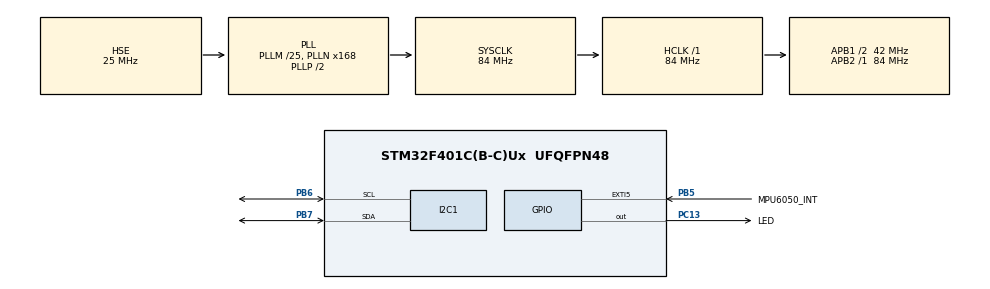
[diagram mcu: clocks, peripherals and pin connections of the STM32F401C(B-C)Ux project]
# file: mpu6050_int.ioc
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I2C1.I2C_Mode=I2C_Standard
Mcu.Family=STM32F4
Mcu.Name=STM32F401C(B-C)Ux
Mcu.Package=UFQFPN48
NVIC.EXTI9_5_IRQn=true\:2\:0\:true\:false\:true\:true\:true\:true
NVIC.I2C1_ER_IRQn=true\:2\:0\:true\:false\:true\:true\:true\:true
NVIC.I2C1_EV_IRQn=true\:2\:0\:true\:false\:true\:true\:true\:true
NVIC.PriorityGroup=NVIC_PRIORITYGROUP_4
PA13.Mode=Trace_Asynchronous_SW
PA13.Signal=SYS_JTMS-SWDIO
PA14.Mode=Trace_Asynchronous_SW
PA14.Signal=SYS_JTCK-SWCLK
PB3.Mode=Trace_Asynchronous_SW
PB3.Signal=SYS_JTDO-SWO
PB5.GPIO_Label=MPU6050_INT
PB5.GPIO_PuPd=GPIO_PULLDOWN
PB5.Signal=GPXTI5
PB6.Mode=I2C
PB6.Signal=I2C1_SCL
PB7.Mode=I2C
PB7.Signal=I2C1_SDA
PC13-ANTI_TAMP.GPIO_Label=LED
PC13-ANTI_TAMP.Signal=GPIO_Output
PH0\ -\ OSC_IN.Mode=HSE-External-Oscillator
PH0\ -\ OSC_IN.Signal=RCC_OSC_IN
PH1\ -\ OSC_OUT.Mode=HSE-External-Oscillator
PH1\ -\ OSC_OUT.Signal=RCC_OSC_OUT
ProjectManager.HeapSize=0x200
ProjectManager.StackSize=0x400
ProjectManager.TargetToolchain=STM32CubeIDE
RCC.48MHZClocksFreq_Value=42000000
RCC.AHBFreq_Value=84000000
RCC.APB1CLKDivider=RCC_HCLK_DIV2
RCC.APB1Freq_Value=42000000
RCC.APB1TimFreq_Value=84000000
RCC.APB2Freq_Value=84000000
RCC.APB2TimFreq_Value=84000000
RCC.CortexFreq_Value=84000000
RCC.HCLKFreq_Value=84000000
RCC.HSE_VALUE=25000000
RCC.HSI_VALUE=16000000
RCC.LSE_VALUE=32768
RCC.PLLM=25
RCC.PLLN=168
RCC.PLLSourceVirtual=RCC_PLLSOURCE_HSE
RCC.SYSCLKFreq_VALUE=84000000
RCC.SYSCLKSource=RCC_SYSCLKSOURCE_PLLCLK
RCC.VCOOutputFreq_Value=168000000
board=custom

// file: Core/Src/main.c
/* USER CODE BEGIN Header */
/**
  ******************************************************************************
  * @file           : main.c
  * @brief          : Main program body
  ******************************************************************************
  * @attention
  *
  * Copyright (c) 2023 STMicroelectronics.
  * All rights reserved.
  *
  * This software is licensed under terms that can be found in the LICENSE file
  * in the root directory of this software component.
  * If no LICENSE file comes with this software, it is provided AS-IS.
  *
  ******************************************************************************
  */
/* USER CODE END Header */
#include "main.h"
#include "i2c.h"
#include "gpio.h"

/* USER CODE BEGIN Includes */
#include "mpu6050.h"
#include "stdio.h"
/* USER CODE END Includes */

void SystemClock_Config(void);
/* USER CODE BEGIN PFP */
int _write(int file, char *ptr, int len){
	int i = 0;
	for (i = 0; i < len; i++)
		ITM_SendChar((*ptr++));
	return len;
}

/* USER CODE END PFP */

int main(void)
{

  /* MCU Configuration--------------------------------------------------------*/

  /* Reset of all peripherals, Initializes the Flash interface and the Systick. */
  HAL_Init();

  /* Configure the system clock */
  SystemClock_Config();

  /* Initialize all configured peripherals */
  MX_GPIO_Init();
  MX_I2C1_Init();
  /* USER CODE BEGIN 2 */
  uint8_t res = mpu6050_init(&hi2c1);
  printf("res : %d",res);
	  uint8_t check=0;
  /* USER CODE END 2 */

  /* Infinite loop */
  while (1)
  {
	  HAL_StatusTypeDef res = HAL_I2C_Mem_Read(&hi2c1, MPU6050_ADDRESS, MPU6050_INT_STATUS, 1, &check, 1,100);

  }
}

void SystemClock_Config(void)
{
  RCC_OscInitTypeDef RCC_OscInitStruct = {0};
  RCC_ClkInitTypeDef RCC_ClkInitStruct = {0};

  /** Configure the main internal regulator output voltage
  */
  __HAL_RCC_PWR_CLK_ENABLE();
  __HAL_PWR_VOLTAGESCALING_CONFIG(PWR_REGULATOR_VOLTAGE_SCALE2);

  /** Initializes the RCC Oscillators according to the specified parameters
  * in the RCC_OscInitTypeDef structure.
  */
  RCC_OscInitStruct.OscillatorType = RCC_OSCILLATORTYPE_HSE;
  RCC_OscInitStruct.HSEState = RCC_HSE_ON;
  RCC_OscInitStruct.PLL.PLLState = RCC_PLL_ON;
  RCC_OscInitStruct.PLL.PLLSource = RCC_PLLSOURCE_HSE;
  RCC_OscInitStruct.PLL.PLLM = 25;
  RCC_OscInitStruct.PLL.PLLN = 168;
  RCC_OscInitStruct.PLL.PLLP = RCC_PLLP_DIV2;
  RCC_OscInitStruct.PLL.PLLQ = 4;
  if (HAL_RCC_OscConfig(&RCC_OscInitStruct) != HAL_OK)
  {
    Error_Handler();
  }

  /** Initializes the CPU, AHB and APB buses clocks
  */
  RCC_ClkInitStruct.ClockType = RCC_CLOCKTYPE_HCLK|RCC_CLOCKTYPE_SYSCLK
                              |RCC_CLOCKTYPE_PCLK1|RCC_CLOCKTYPE_PCLK2;
  RCC_ClkInitStruct.SYSCLKSource = RCC_SYSCLKSOURCE_PLLCLK;
  RCC_ClkInitStruct.AHBCLKDivider = RCC_SYSCLK_DIV1;
  RCC_ClkInitStruct.APB1CLKDivider = RCC_HCLK_DIV2;
  RCC_ClkInitStruct.APB2CLKDivider = RCC_HCLK_DIV1;

  if (HAL_RCC_ClockConfig(&RCC_ClkInitStruct, FLASH_LATENCY_2) != HAL_OK)
  {
    Error_Handler();
  }
}

/* USER CODE BEGIN 4 */
void HAL_GPIO_EXTI_Callback(uint16_t GPIO_Pin){
	if(GPIO_Pin == MPU6050_INT_Pin){
		printf("interrupt raised");
	}
	__HAL_GPIO_EXTI_CLEAR_IT(GPIO_Pin);
}

/* USER CODE END 4 */

void Error_Handler(void)
{
  __disable_irq();
  while (1)
  {
  }
}
